# LPC15xx register map
File version: 0.7
CPU: CM3 r2p1, little endian, no MPU, no FPU, 3 interrupt priority bits
Registers are 32-bit, read-write, reset 0x0 unless marked. A register's access mark holds for its fields unless they carry their own. Offsets are from the block's base; [hi:lo] are bit positions; {n}, {i} and the like mark numbered series; 'fields as' and 'values as' point back to an identical list.

## ADC0 — 12-bit ADC controller ADC0/1
Base 0x40000000
Same registers: ADC1 0x40080000
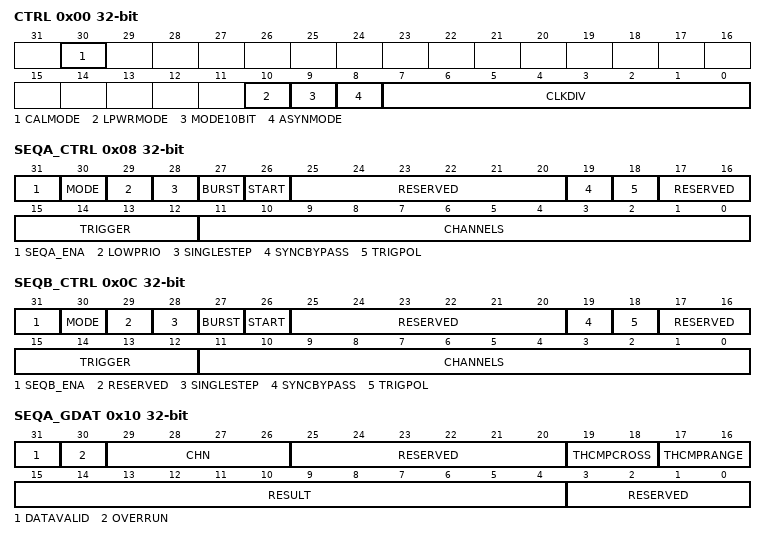
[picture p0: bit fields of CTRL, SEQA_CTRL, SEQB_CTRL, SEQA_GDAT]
0x00 CTRL — A/D Control Register. Contains the clock divide value, enable bits for each sequence and the A/D power-down bit.
  [30] CALMODE — Writing a 1 to this bit initiates a self-calibration cycle. This bit will be automatically cleared by hardware after the calibration cycle is complete. Other bits of this register may be written to concurrently with setting this bit, however once this bit has been set no further writes to this register are permitted until the full calibration cycle has ended.
  [10] LPWRMODE — Select low-power ADC mode. The analog circuitry is automatically powered-down when no conversions are taking place. When any (hardware or software) triggering event is detected, the analog circuitry is enabled. After the required start-up time, the requested conversion will be launched. Once the conversion completes, the analog-circuitry will again be powered-down provided no further conversions are pending. Using this mode can save an appreciable amount of current (approximately 2.5 mA) when conversions are required relatively infrequently. The penalty for using this mode is an approximately 15 ADC clock delay (30 clocks in 10-bit mode), based on the frequency specified in the CLKDIV field, from the time the trigger event occurs until sampling of the A/D input commences. This mode will NOT power-up the A/D if the ADC_ENA bit is low.
    0=DISABLED (Disabled. The low-power ADC mode is disabled. The analog circuitry remains activated even when no conversions are requested.); 1=ENABLED (Enabled. The low-power ADC mode is enabled.)
  [9] MODE10BIT — Select 10-bit conversion. In 10-bit mode higher conversion rates of up to 100 MHz are supported. A/D resolution is reduced to ten bits, but the clock rate (set via the CLKDIV field) can be increased up to 100 MHz to achieve a conversion rate of up to four million samples per second. The two LSBs of the result data are forced to zero.
    0=DISABLED (Disabled. The 10-bit/high-conversion rate mode is disabled.); 1=ENABLED (Enabled. The 10-bit/high-conversion rate is enabled.)
  [8] ASYNMODE — Select clock mode.
    0=SYNCHRONOUS_MODE (Synchronous mode. The ADC clock is derived from the system clock based on the divide value selected in the CLKDIV field. The ADC clock will be started in a controlled fashion in response to a trigger to eliminate any uncertainty in the launching of an ADC conversion in response to any synchronous (on-chip) trigger. In Synchronous mode with the SYNCBYPASS bit set, sampling of the A/D input and start of conversion will initiate exactly 2 system clocks after the leading edge of a (synchronous) trigger pulse.); 1=ASYNCHRONOUS_MODE (Asynchronous mode. The ADC clock is based on the output of the asynchronous ADC clock divider ADCASYNCCLKSEL in the SYSCON block. The frequency of this clock is limited to 50 MHz max (100 MHz in 10-bit mode). In addition, the ADC clock must never be faster than 10x the system clock.)
  [7:0] CLKDIV — In synchronous mode only, the system clock is divided by this value plus one to produce the clock for the A/D converter, which should be less than or equal to 50 MHz (up to 100 MHz in 10-bit mode). Typically, software should program the smallest value in this field that yields this maximum clock rate or slightly less, but in certain cases (such as a high-impedance analog source) a slower clock may be desirable. This field is ignored in the asynchronous operating mode.
0x04 INSEL — A/D Input Select Register: Selects between external pin and internal source for various channels
  [3:0] AD0SEL — This field selects the input source for channel 0. All other values are reserved.
    0=ADCN_0_PIN (ADCn_0 pin. Voltage on ADC channel 0 input.); 1=CORE_VOLTAGE_REGULAT (Core voltage regulator output (1.2V to 1.8V). If the WRAPEN field is 0x2, the core voltage regulator output is also is output on the ADC0/1_0 pin.); 2=INTERNAL_VOLTAGE_REF (Internal voltage reference. If the WRAPEN field is 0x2, the internal voltage reference is also is output on the ADCn_0 pin.); 3=TEMPERATURE_SENSOR (Temperature Sensor. If the WRAPEN field is 0x2, the temperature sensor voltage is also is output on the ADCn_0 pin.); 4=VDDADIV2 (VDDA/2.); 15=NO_CONNECTION_OR_LOA (No connection or load)
0x08 SEQA_CTRL — A/D Conversion Sequence-A control Register: Controls triggering and channel selection for conversion sequence-A. Also specifies interrupt mode for sequence-A.
  [31] SEQA_ENA — Sequence Enable
    0=DISABLED (Disabled. Sequence A is disabled. Sequence A triggers are ignored. If this bit is cleared while sequence A is in progress, the sequence will be halted at the end of the current conversion. After the sequence is re-enabled, a new trigger will be required to restart the sequence beginning with the next enabled channel.); 1=ENABLED (Enabled. Sequence A is enabled.)
  [30] MODE — Indicates whether the primary method for retrieving conversion results for this sequence will be accomplished via reading the global data register (SEQA_GDAT) at the end of each conversion, or the individual channel result registers at the end of the entire sequence. Impacts when conversion-complete interrupt/DMA requests for sequence-A will be generated and which overrun conditions contribute to an overrun interrupt as described below:
    0=END_OF_CONVERSION (End of conversion. The sequence A interrupt/DMA flag will be set at the end of each individual A/D conversion performed under sequence A. This flag will mirror the DATAVALID bit in the SEQA_GDAT register. The OVERRUN bit in the SEQA_GDAT register will contribute to generation of an overrun interrupt/DMA request if enabled.); 1=END_OF_SEQUENCE (End of sequence. The sequence A interrupt/DMA flag will be set when the entire set of sequence-A conversions completes. This flag will need to be explicitly cleared by software or by the DMA-clear signal in this mode. The OVERRUN bit in the SEQA_GDAT register will NOT contribute to generation of an overrun interrupt/DMA request since it is assumed this register may not be utilized in this mode.)
  [29] LOWPRIO — Set priority for sequence A.
    0=LOW_PRIORITY (Low priority. Any B trigger which occurs while an A conversion sequence is active will be ignored and lost.); 1=HIGH_PRIORITY (High priority. Setting this bit to a 1 will permit any enabled B sequence trigger (including a B sequence software start) to immediately interrupt this sequence and launch a B sequence in it's place. The conversion currently in progress will be terminated. The A sequence that was interrupted will automatically resume after the B sequence completes. The channel whose conversion was terminated will be re-sampled and the conversion sequence will resume from that point.)
  [28] SINGLESTEP — When this bit is set, a hardware trigger or a write to the START bit will launch a single conversion on the next channel in the sequence instead of the default response of launching an entire sequence of conversions. Once all of the channels comprising a sequence have been converted, a subsequent trigger will repeat the sequence beginning with the first enabled channel. Interrupt generation will still occur either after each individual conversion or at the end of the entire sequence, depending on the state of the MODE bit.
  [27] BURST — Writing a 1 to this bit will cause this conversion sequence to be continuously cycled through. Other sequence A triggers will be ignored while this bit is set. Repeated conversions can be halted by clearing this bit. The sequence currently in progress will be completed before conversions are terminated.
  [26] START — Writing a 1 to this field will launch one pass through this conversion sequence. The behavior will be identical to a sequence triggered by a hardware trigger. Do not write 1 to this bit if the BURST bit is set. This bit is only set to a 1 momentarily when written-to to launch a conversion sequence. It will consequently always read-back as a zero.
  [25:20] RESERVED — Reserved, user software should not write ones to reserved bits. The value read from a reserved bit is not defined.
  [19] SYNCBYPASS — Setting this bit allows the hardware trigger input to bypass synchronization flip-flops stages and therefore shorten the time between the trigger input signal and the start of a conversion. There are slightly different criteria for whether or not this bit can be set depending on the clock operating mode: Synchronous mode: Synchronization may be bypassed (this bit may be set) if the selected trigger source is already synchronous with the main system clock (eg. coming from an on-chip, system-clock-based timer). Whether this bit is set or not, a trigger pulse must be maintained for at least one system clock period. Asynchronous mode: Synchronization may be bypassed (this bit may be set) if it is certain that the duration of a trigger input pulse will be at least one cycle of the ADC clock (regardless of whether the trigger comes from and on-chip or off-chip source). If this bit is NOT set, the trigger pulse must at least be maintained for one system clock period.
    0=ENABLE_SYNCHRONIZATI (Enable synchronization. The hardware trigger bypass is not enabled.); 1=BYPASS_SYNCHRONIZATI (Bypass synchronization. The hardware trigger bypass is enabled.)
  [18] TRIGPOL — Select the polarity of the selected input trigger for this conversion sequence.
    0=NEGATIVE_EDGE (Negative edge. A negative edge launches the conversion sequence on the selected trigger input.); 1=POSITIVE_EDGE (Positive edge. A positive edge launches the conversion sequence on the selected trigger input.)
  [17:16] RESERVED — Reserved, user software should not write ones to reserved bits. The value read from a reserved bit is not defined.
  [15:12] TRIGGER — Selects which of the available hardware trigger sources will cause this conversion sequence to be initiated. Program the trigger input number in this field.
  [11:0] CHANNELS — Selects which one or more of the twelve channels will be sampled and converted when this sequence is launched. A 1 in any bit of this field will cause the corresponding channel to be included in the conversion sequence, where bit 0 corresponds to channel 0, bit 1 to channel 1 and so forth. When this conversion sequence is triggered, either by a hardware trigger or via software command, A/D conversions will be performed on each enabled channel, in sequence, beginning with the lowest-ordered channel. This field can ONLY be changed while the SEQA_ENA bit (bit 31) is LOW. It is allowed to change this field and set bit 31 in the same write.
0x0C SEQB_CTRL — A/D Conversion Sequence-B Control Register: Controls triggering and channel selection for conversion sequence-B. Also specifies interrupt mode for sequence-B.
  [31] SEQB_ENA — Sequence Enable
    0=DISABLED (Disabled. Sequence B is disabled. Sequence B triggers are ignored. If this bit is cleared while sequence B is in progress, the sequence will be halted at the end of the current conversion. After the sequence is re-enabled, a new trigger will be required to restart the sequence beginning with the next enabled channel.); 1=ENABLED (Enabled. Sequence B is enabled.)
  [30] MODE — Indicates whether the primary method for retrieving conversion results for this sequence will be accomplished via reading the global data register (SEQB_GDAT) at the end of each conversion, or the individual channel result registers at the end of the entire sequence. Impacts when conversion-complete interrupt/DMA requests for sequence-B will be generated and which overrun conditions contribute to an overrun interrupt as described below:
    0=END_OF_CONVERSION (End of conversion. The sequence B interrupt/DMA flag will be set at the end of each individual A/D conversion performed under sequence B. This flag will mirror the DATAVALID bit in the SEQB_GDAT register. The OVERRUN bit in the SEQB_GDAT register will contribute to generation of an overrun interrupt/DMA request if enabled.); 1=END_OF_SEQUENCE (End of sequence. The sequence B interrupt/DMA flag will be set when the entire set of sequence B conversions completes. This flag will need to be explicitly cleared by software or by the DMA-clear signal in this mode. The OVERRUN bit in the SEQB_GDAT register will NOT contribute to generation of an overrun interrupt/DMA request since it is assumed this register will not be utilized in this mode.)
  [29] RESERVED — Reserved, user software should not write ones to reserved bits. The value read from a reserved bit is not defined.
  [28] SINGLESTEP — When this bit is set, a hardware trigger or a write to the START bit will launch a single conversion on the next channel in the sequence instead of the default response of launching an entire sequence of conversions. Once all of the channels comprising a sequence have been converted, a subsequent trigger will repeat the sequence beginning with the first enabled channel. Interrupt generation will still occur either after each individual conversion or at the end of the entire sequence, depending on the state of the MODE bit.
  [27] BURST — Writing a 1 to this bit will cause this conversion sequence to be continuously cycled through. Other B triggers will be ignored while this bit is set. Repeated conversions can be halted by clearing this bit. The sequence currently in progress will be completed before conversions are terminated.
  [26] START — Writing a 1 to this field will launch one pass through this conversion sequence. The behavior will be identical to a sequence triggered by a hardware trigger. Do not write a 1 to this bit if the BURST bit is set. This bit is only set to a 1 momentarily when written-to to launch a conversion sequence. It will consequently always read-back as a zero.
  [25:20] RESERVED — Reserved, user software should not write ones to reserved bits. The value read from a reserved bit is not defined.
  [19] SYNCBYPASS — Setting this bit allows the hardware trigger input to bypass synchronization flip-flops stages and therefore shorten the time between the trigger input signal and the start of a conversion. There are slightly different criteria for whether or not this bit can be set depending on the clock operating mode: Synchronous mode: Synchronization may be bypassed (this bit may be set) if the selected trigger source is already synchronous with the main system clock (eg. coming from an on-chip, system-clock-based timer). Whether this bit is set or not, a trigger pulse must be maintained for at least one system clock period. Asynchronous mode: Synchronization may be bypassed (this bit may be set) if it is certain that the duration of a trigger input pulse will be at least one cycle of the ADC clock (regardless of whether the trigger comes from and on-chip or off-chip source). If this bit is NOT set, the trigger pulse must at least be maintained for one system clock period.
    values as SEQA_CTRL.SYNCBYPASS
  [18] TRIGPOL — Select the polarity of the selected input trigger for this conversion sequence.
    values as SEQA_CTRL.TRIGPOL
  [17:16] RESERVED — Reserved, user software should not write ones to reserved bits. The value read from a reserved bit is not defined.
  [15:12] TRIGGER — Selects which of the available hardware trigger sources will cause this conversion sequence to be initiated. Program the trigger input number in this field.
  [11:0] CHANNELS — Selects which one or more of the twelve channels will be sampled and converted when this sequence is launched. A 1 in any bit of this field will cause the corresponding channel to be included in the conversion sequence, where bit 0 corresponds to channel 0, bit 1 to channel 1 and so forth. When this conversion sequence is triggered, either by a hardware trigger or via software command, A/D conversions will be performed on each enabled channel, in sequence, beginning with the lowest-ordered channel. This field can ONLY be changed while the SEQB_ENA bit (bit 31) is LOW. It is permissible to change this field and set bit 31 in the same write.
0x10 SEQA_GDAT reset not defined — A/D Sequence-A Global Data Register. This register contains the result of the most recent A/D conversion performed under sequence-A
  [31] DATAVALID — This bit is set to 1 at the end of each conversion when a new result is loaded into the RESULT field. It is cleared whenever this register is read. This bit will cause a conversion-complete interrupt for the corresponding sequence if the MODE bit (in SEQA_CTRL) for that sequence is set to 0 (and if the interrupt is enabled).
  [30] OVERRUN — This bit is set if a new conversion result is loaded into the RESULT field before a previous result has been read - i.e. while the DATAVALID bit is set. This bit is cleared, along with the DATAVALID bit, whenever this register is read. This bit will contribute to an overrun interrupt request if the MODE bit (in SEQA_CTRL) for the corresponding sequence is set to 0 (and if the overrun interrupt is enabled).
  [29:26] CHN — These bits contain the channel from which the RESULT bits were converted (e.g. 0000 identifies channel 0, 0001 channel 1...).
  [25:20] RESERVED — Reserved, user software should not write ones to reserved bits. The value read from a reserved bit is not defined.
  [19:18] THCMPCROSS — Indicates whether the result of the last conversion performed represented a crossing of the threshold level established by the designated LOW threshold comparison register (THRn_LOW) and, if so, in what direction the crossing occurred.
  [17:16] THCMPRANGE — Indicates whether the result of the last conversion performed was above, below or within the range established by the designated threshold comparison registers (THRn_LOW and THRn_HIGH).
  [15:4] RESULT — This field contains the 12-bit A/D conversion result from the most recent conversion performed under conversion sequence associated with this register. The result is the a binary fraction representing the voltage on the currently-selected input channel as it falls within the range of VREFP to VREFN. Zero in the field indicates that the voltage on the input pin was less than, equal to, or close to that on VREFN, while 0xFFF indicates that the voltage on the input was close to, equal to, or greater than that on VREFP. DATAVALID = 1 indicates that this result has not yet been read.
  [3:0] RESERVED — Reserved, user software should not write ones to reserved bits. The value read from a reserved bit is not defined.
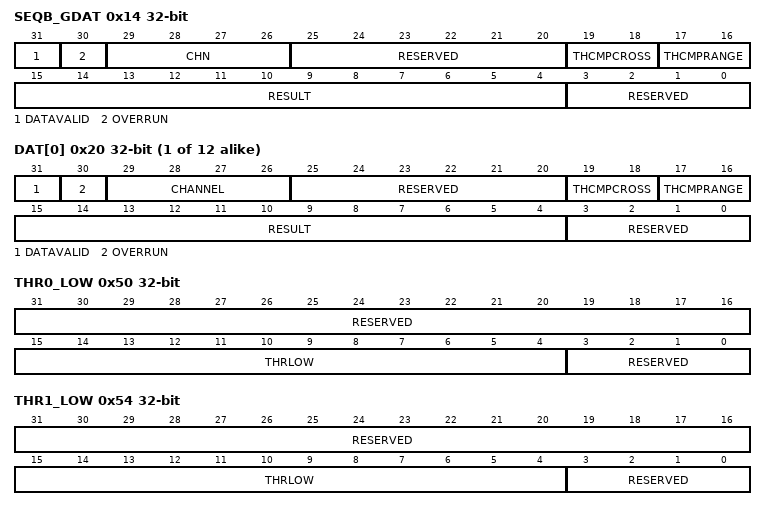
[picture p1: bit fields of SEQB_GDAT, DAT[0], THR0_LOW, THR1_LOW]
0x14 SEQB_GDAT reset not defined — A/D Sequence-B Global Data Register. This register contains the result of the most recent A/D conversion performed under sequence-B
  [31] DATAVALID — This bit is set to 1 at the end of each conversion when a new result is loaded into the RESULT field. It is cleared whenever this register is read. This bit will cause a conversion-complete interrupt for the corresponding sequence if the MODE bit (in SEQB_CTRL) for that sequence is set to 0 (and if the interrupt is enabled).
  [30] OVERRUN — This bit is set if a new conversion result is loaded into the RESULT field before a previous result has been read - i.e. while the DATAVALID bit is set. This bit is cleared, along with the DATAVALID bit, whenever this register is read. This bit will contribute to an overrun interrupt request if the MODE bit (in SEQB_CTRL) for the corresponding sequence is set to 0 (and if the overrun interrupt is enabled).
  [29:26] CHN — These bits contain the channel from which the RESULT bits were converted (e.g. 0b0000 identifies channel 0, 0b0001 channel 1...).
  [25:20] RESERVED — Reserved, user software should not write ones to reserved bits. The value read from a reserved bit is not defined.
  [19:18] THCMPCROSS — Indicates whether the result of the last conversion performed represented a crossing of the threshold level established by the designated LOW threshold comparison register (THRn_LOW) and, if so, in what direction the crossing occurred. 0x0 = No threshold Crossing detected: The most recent completed conversion on this channel had the same relationship (above or below) to the threshold value established by the designated LOW threshold register (THRn_LOW) as did the previous conversion on this channel. 0x1 = Reserved. 0x2 = Downward Threshold Crossing Detected. Indicates that a threshold crossing in the downward direction has occurred - i.e. the previous sample on this channel was above the threshold value established by the designated LOW threshold register (THRn_LOW) and the current sample is below that threshold. 0x3 = Upward Threshold Crossing Detected. Indicates that a threshold crossing in the upward direction has occurred - i.e. the previous sample on this channel was below the threshold value established by the designated LOW threshold register (THRn_LOW) and the current sample is above that threshold.
  [17:16] THCMPRANGE — Indicates whether the result of the last conversion performed was above, below or within the range established by the designated threshold comparison registers (THRn_LOW and THRn_HIGH). Threshold Range Comparison result. 0x0 = In Range: The last completed conversion was greater than or equal to the value programmed into the designated LOW threshold register (THRn_LOW) but less than or equal to the value programmed into the designated HIGH threshold register (THRn_HIGH). 0x1 = Below Range: The last completed conversion on was less than the value programmed into the designated LOW threshold register (THRn_LOW). 0x2 = Above Range: The last completed conversion was greater than the value programmed into the designated HIGH threshold register (THRn_HIGH). 0x3 = Reserved.
  [15:4] RESULT — This field contains the 12-bit A/D conversion result from the most recent conversion performed under conversion sequence associated with this register. This will be a binary fraction representing the voltage on the currently-selected input channel as it falls within the range of VREFP to VREFN. Zero in the field indicates that the voltage on the input pin was less than, equal to, or close to that on VREFN, while 0xFFF indicates that the voltage on the input was close to, equal to, or greater than that on V REFP. DATAVALID = 1 indicates that this result has not yet been read.
  [3:0] RESERVED — Reserved, user software should not write ones to reserved bits. The value read from a reserved bit is not defined.
{0x20+4i} DAT[{i}] (i=0..11) ro reset not defined — A/D Channel 0 Data Register. This register contains the result of the most recent conversion completed on channel 0.
  [31] DATAVALID — This bit is set to 1 when an A/D conversion on this channel completes. This bit is cleared whenever this register is read or when the data related to this channel is read from either of the global SEQn_GDAT registers. While it is allowed to include the same channels in both conversion sequences, doing so may cause erratic behavior of the DONE and OVERRUN bits in the data registers associated with any of the channels that are shared between the two sequences. Any erratic OVERRUN behavior will also affect overrun interrupt generation, if enabled.
  [30] OVERRUN — This bit will be set to a 1 if a new conversion on this channel completes and overwrites the previous contents of the RESULT field before it has been read - i.e. while the DONE bit is set. This bit is cleared, along with the DONE bit, whenever this register is read or when the data related to this channel is read from either of the global SEQn_GDAT registers. This bit (in any of the 12 registers) will cause an overrun interrupt request to be asserted if the overrun interrupt is enabled. While it is allowed to include the same channels in both conversion sequences, doing so may cause erratic behavior of the DONE and OVERRUN bits in the data registers associated with any of the channels that are shared between the two sequences. Any erratic OVERRUN behavior will also affect overrun interrupt generation, if enabled.
  [29:26] CHANNEL — This field is hard-coded to contain the channel number that this particular register relates to (i.e. this field will contain 0b0000 for the DAT0 register, 0b0001 for the DAT1 register, etc)
  [25:20] RESERVED — Reserved, user software should not write ones to reserved bits. The value read from a reserved bit is not defined.
  [19:18] THCMPCROSS — Threshold Crossing Comparison result. 0x0 = No threshold Crossing detected: The most recent completed conversion on this channel had the same relationship (above or below) to the threshold value established by the designated LOW threshold register (THRn_LOW) as did the previous conversion on this channel. 0x1 = Reserved. 0x2 = Downward Threshold Crossing Detected. Indicates that a threshold crossing in the downward direction has occurred - i.e. the previous sample on this channel was above the threshold value established by the designated LOW threshold register (THRn_LOW) and the current sample is below that threshold. 0x3 = Upward Threshold Crossing Detected. Indicates that a threshold crossing in the upward direction has occurred - i.e. the previous sample on this channel was below the threshold value established by the designated LOW threshold register (THRn_LOW) and the current sample is above that threshold.
  [17:16] THCMPRANGE — Threshold Range Comparison result. 0x0 = In Range: The last completed conversion was greater than or equal to the value programmed into the designated LOW threshold register (THRn_LOW) but less than or equal to the value programmed into the designated HIGH threshold register (THRn_HIGH). 0x1 = Below Range: The last completed conversion on was less than the value programmed into the designated LOW threshold register (THRn_LOW). 0x2 = Above Range: The last completed conversion was greater than the value programmed into the designated HIGH threshold register (THRn_HIGH). 0x3 = Reserved.
  [15:4] RESULT — This field contains the 12-bit A/D conversion result from the last conversion performed on this channel. This will be a binary fraction representing the voltage on the AD0[n] pin, as it falls within the range of VREFP to VREFN. Zero in the field indicates that the voltage on the input pin was less than, equal to, or close to that on VREFN, while 0xFFF indicates that the voltage on the input was close to, equal to, or greater than that on VREFP.
  [3:0] RESERVED — Reserved, user software should not write ones to reserved bits. The value read from a reserved bit is not defined.
0x50 THR0_LOW — A/D Low Compare Threshold Register 0 : Contains the lower threshold level for automatic threshold comparison for any channels linked to threshold pair 0.
  [31:16] RESERVED — Reserved, user software should not write ones to reserved bits. The value read from a reserved bit is not defined.
  [15:4] THRLOW — Low threshold value against which A/D results will be compared
  [3:0] RESERVED — Reserved, user software should not write ones to reserved bits. The value read from a reserved bit is not defined.
0x54 THR1_LOW — A/D Low Compare Threshold Register 1: Contains the lower threshold level for automatic threshold comparison for any channels linked to threshold pair 1.
  fields as THR0_LOW
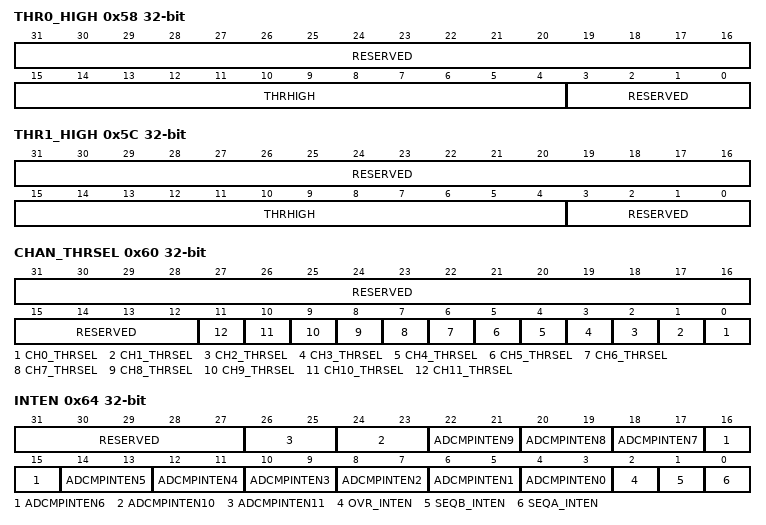
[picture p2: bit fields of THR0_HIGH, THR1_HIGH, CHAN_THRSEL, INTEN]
0x58 THR0_HIGH — A/D High Compare Threshold Register 0: Contains the upper threshold level for automatic threshold comparison for any channels linked to threshold pair 0.
  [31:16] RESERVED — Reserved, user software should not write ones to reserved bits. The value read from a reserved bit is not defined.
  [15:4] THRHIGH — High threshold value against which A/D results will be compared
  [3:0] RESERVED — Reserved, user software should not write ones to reserved bits. The value read from a reserved bit is not defined.
0x5C THR1_HIGH — A/D High Compare Threshold Register 1: Contains the upper threshold level for automatic threshold comparison for any channels linked to threshold pair 1.
  fields as THR0_HIGH
0x60 CHAN_THRSEL ro — A/D Channel-Threshold Select Register. Specifies which set of threshold compare registers are to be used for each channel
  [31:12] RESERVED — Reserved, user software should not write ones to reserved bits. The value read from a reserved bit is not defined.
  [n] CH{n}_THRSEL (n=0..11) — Threshold select by channel.
    0=THRESHOLD_0 (Threshold 0. Channel {n} results will be compared against the threshold levels indicated in the THR0_LOW and THR0_HIGH registers); 1=THRESHOLD_1 (Threshold 1. Channel {n} results will be compared against the threshold levels indicated in the THR1_LOW and THR1_HIGH registers)
0x64 INTEN — A/D Interrupt Enable Register. This register contains enable bits that enable the sequence-A, sequence-B, threshold compare and data overrun interrupts to be generated.
  [31:27] RESERVED — Reserved, user software should not write ones to reserved bits. The value read from a reserved bit is not defined.
  [2n+4:2n+3] ADCMPINTEN{n} (n=0..11) — Threshold comparison interrupt enable.
    0=DISABLED; 1=OUTSIDE_THRESHOLD; 2=CROSSING_THRESHOLD
  [2] OVR_INTEN — Overrun interrupt enable.
    0=DISABLED (Disabled. The overrun interrupt is disabled.); 1=ENABLED (Enabled. The overrun interrupt is enabled. Detection of an overrun condition on any of the 12 channel data registers will cause an overrun interrupt request. In addition, if the MODE bit for a particular sequence is 0, then an overrun in the global data register for that sequence will also cause this interrupt request to be asserted.)
  [1] SEQB_INTEN — Sequence B interrupt enable.
    0=DISABLED (Disabled. The sequence B interrupt/DMA request is disabled.); 1=ENABLED (Enabled. The sequence B interrupt/DMA request is enabled and will be asserted either upon completion of each individual conversion performed as part of sequence B, or upon completion of the entire B sequence of conversions, depending on the MODE bit in the SEQB_CTRL register.)
  [0] SEQA_INTEN — Sequence A interrupt enable.
    0=DISABLED (Disabled. The sequence A interrupt/DMA request is disabled.); 1=ENABLED (Enabled. The sequence A interrupt/DMA request is enabled and will be asserted either upon completion of each individual conversion performed as part of sequence A, or upon completion of the entire A sequence of conversions, depending on the MODE bit in the SEQA_CTRL register.)
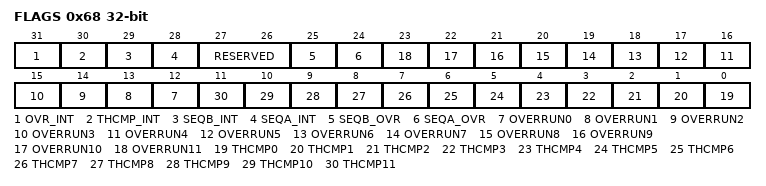
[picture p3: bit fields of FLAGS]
0x68 FLAGS ro — A/D Flags Register. Contains the four interrupt request flags and the individual component overrun and threshold-compare flags. (The overrun bits replicate information stored in the result registers).
  [31] OVR_INT — Overrun Interrupt flag. Any overrun bit in any of the individual channel data registers will cause this interrupt. In addition, if the MODE bit in either of the SEQn_CTRL registers is 0 then the OVERRUN bit in the corresponding SEQn_GDAT register will also cause this interrupt. This interrupt must be enabled in the INTEN register. This bit will be cleared when all of the individual overrun bits have been cleared via reading the corresponding data registers.
  [30] THCMP_INT — Threshold Comparison Interrupt/DMA flag. This bit will be set if any of the 12 THCMP flags in the lower bits of this register are set to 1 (due to an enabled out-of-range or threshold-crossing event on any channel). Each type of threshold comparison interrupt on each channel must be individually enabled in the INTEN register to cause this interrupt. This bit will be cleared when all of the component flags in bits 11:0 are cleared via writing 1s to those bits.
  [29] SEQB_INT — Sequence A interrupt/DMA flag. If the MODE bit in the SEQB_CTRL register is 0, this flag will mirror the DATAVALID bit in the sequence A global data register (SEQB_GDAT), which is set at the end of every A/D conversion performed as part of sequence B. It will be cleared automatically when the SEQB_GDAT register is read. If the MODE bit in the SEQB_CTRL register is 1, this flag will be set upon completion of an entire B sequence. In this case it must be cleared by writing a 1 to this SEQB_INT bit. This interrupt must be enabled in the INTEN register.
  [28] SEQA_INT — Sequence A interrupt/DMA flag. If the MODE bit in the SEQA_CTRL register is 0, this flag will mirror the DATAVALID bit in the sequence A global data register (SEQA_GDAT), which is set at the end of every A/D conversion performed as part of sequence A. It will be cleared automatically when the SEQA_GDAT register is read. If the MODE bit in the SEQA_CTRL register is 1, this flag will be set upon completion of an entire A sequence. In this case it must be cleared by writing a 1 to this SEQA_INT bit. This interrupt must be enabled in the INTEN register.
  [27:26] RESERVED — Reserved, user software should not write ones to reserved bits. The value read from a reserved bit is not defined.
  [25] SEQB_OVR — Mirrors the global OVERRUN status flag in the SEQB_GDAT register
  [24] SEQA_OVR — Mirrors the global OVERRUN status flag in the SEQA_GDAT register
  [n+12] OVERRUN{n} (n=0..11) — Mirrors the OVERRRUN status flag from the result register for A/D channel {n}
  [n] THCMP{n} (n=0..11) — Threshold comparison event on Channel {n}. Set to 1 upon either an out-of-range result or a threshold-crossing result if enabled to do so in the INTEN register. This bit is cleared by writing a 1.
0x6C TRM reset 0xF00 — ADC trim register.
  [5] VRANGE — Reserved.
    0=HIGH_VOLTAGE (High voltage. VDDA = 2.7 V to 3.6 V.); 1=LOW_VOLTAGE (Low voltage. VDDA = 2.4 V to 2.7 V.)
